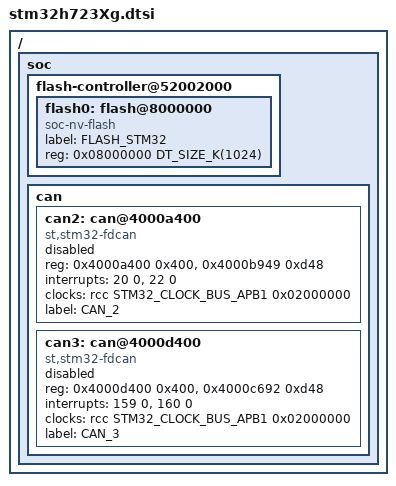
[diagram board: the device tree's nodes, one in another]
/*
 * Copyright (c) 2020 Alexander Kozhinov <AlexanderKozhinov@yandex.com>
 * SPDX-License-Identifier: Apache-2.0
 */

#include <mem.h>
#include <st/h7/stm32h723.dtsi>

/ {
	soc {
		flash-controller@52002000 {
			flash0: flash@8000000 {
				compatible = "soc-nv-flash";
				label = "FLASH_STM32";
				reg = <0x08000000 DT_SIZE_K(1024)>;
			};
		};

		can {
			can2: can@4000a400 {
				compatible = "st,stm32-fdcan";
				#address-cells = <1>;
				#size-cells = <0>;
				reg = <0x4000a400 0x400>, <0x4000b949 0xd48>;
				reg-names = "m_can", "message_ram";
				interrupts = <20 0>, <22 0>;
				interrupt-names = "LINE_0", "LINE_1";
				clocks = <&rcc STM32_CLOCK_BUS_APB1 0x02000000>;
				status = "disabled";
				label = "CAN_2";
			};

			can3: can@4000d400 {
				compatible = "st,stm32-fdcan";
				#address-cells = <1>;
				#size-cells = <0>;
				reg = <0x4000d400 0x400>, <0x4000c692 0xd48>;
				reg-names = "m_can", "message_ram";
				interrupts = <159 0>, <160 0>;
				interrupt-names = "LINE_0", "LINE_1";
				clocks = <&rcc STM32_CLOCK_BUS_APB1 0x02000000>;
				status = "disabled";
				label = "CAN_3";
			};
		};
	};
};
